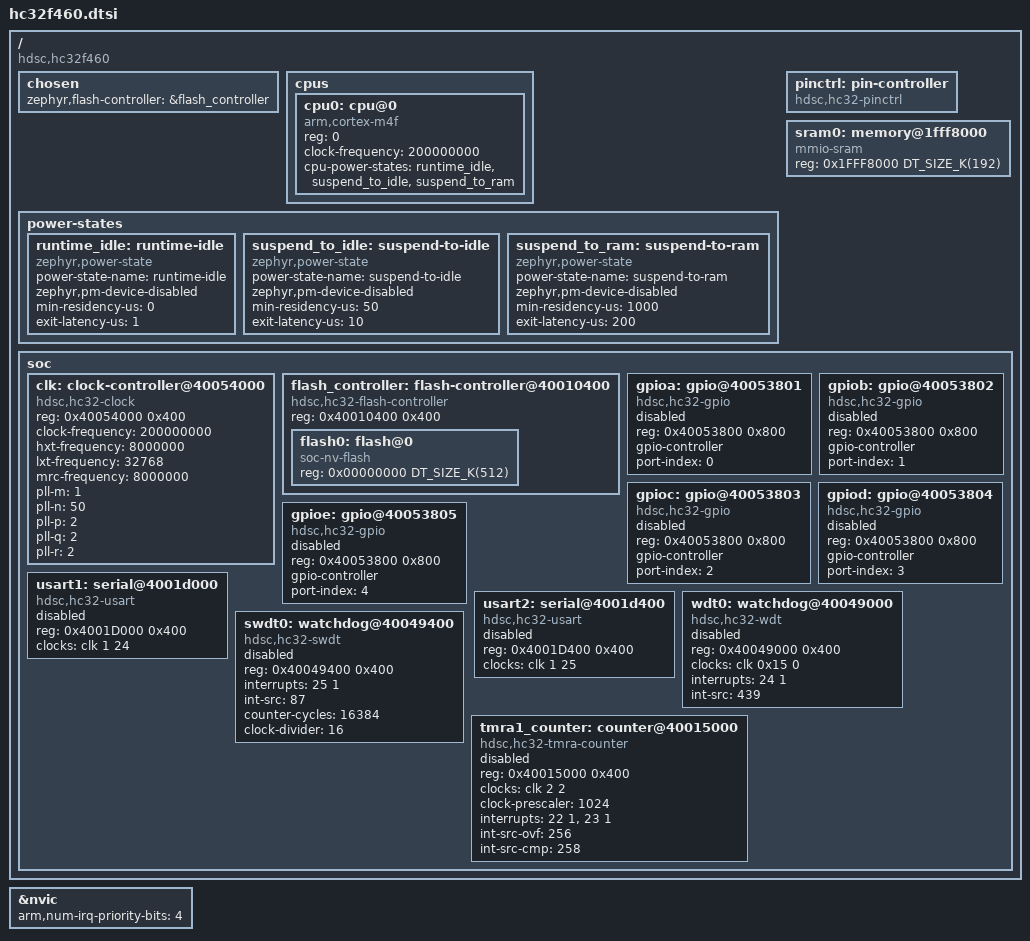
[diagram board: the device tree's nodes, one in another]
/*
 * SPDX-License-Identifier: Apache-2.0
 *
 * HC32F460 SoC devicetree include
 *
 * Memory map:
 *   Flash: 0x00000000, 512K
 *   SRAM:  0x1FFF8000, 192K (188K general + 4K ret_ram)
 */

#include <arm/armv7-m.dtsi>
#include <zephyr/dt-bindings/gpio/gpio.h>
#include <mem.h>

/ {
	compatible = "hdsc,hc32f460";

	chosen {
		zephyr,flash-controller = &flash_controller;
	};

	cpus {
		#address-cells = <1>;
		#size-cells = <0>;
		cpu0: cpu@0 {
			device_type = "cpu";
			compatible = "arm,cortex-m4f";
			reg = <0>;
			clock-frequency = <200000000>; /* HXT 8 MHz -> PLL 200 MHz */
			cpu-power-states = <&runtime_idle &suspend_to_idle &suspend_to_ram>;
		};
	};

	power-states {
		runtime_idle: runtime-idle {
			compatible = "zephyr,power-state";
			power-state-name = "runtime-idle";
			zephyr,pm-device-disabled;
			min-residency-us = <0>;
			exit-latency-us = <1>;
		};

		suspend_to_idle: suspend-to-idle {
			compatible = "zephyr,power-state";
			power-state-name = "suspend-to-idle";
			zephyr,pm-device-disabled;
			min-residency-us = <50>;
			exit-latency-us = <10>;
		};

		suspend_to_ram: suspend-to-ram {
			compatible = "zephyr,power-state";
			power-state-name = "suspend-to-ram";
			zephyr,pm-device-disabled;
			min-residency-us = <1000>;
			exit-latency-us = <200>;
		};
	};

	pinctrl: pin-controller {
		compatible = "hdsc,hc32-pinctrl";
		status = "okay";
	};

	sram0: memory@1fff8000 {
		compatible = "mmio-sram";
		reg = <0x1FFF8000 DT_SIZE_K(192)>;
	};

	soc {
		clk: clock-controller@40054000 {
			compatible = "hdsc,hc32-clock";
			reg = <0x40054000 0x400>;
			#clock-cells = <2>;
			clock-frequency = <200000000>;
			hxt-frequency = <8000000>;
			lxt-frequency = <32768>;
			mrc-frequency = <8000000>;
			pll-m = <1>;
			pll-n = <50>;
			pll-p = <2>;
			pll-q = <2>;
			pll-r = <2>;
			status = "okay";
		};

		flash_controller: flash-controller@40010400 {
			compatible = "hdsc,hc32-flash-controller";
			reg = <0x40010400 0x400>;
			#address-cells = <1>;
			#size-cells = <1>;

			flash0: flash@0 {
				compatible = "soc-nv-flash";
				reg = <0x00000000 DT_SIZE_K(512)>;
			};
		};

		gpioa: gpio@40053801 {
			compatible = "hdsc,hc32-gpio";
			reg = <0x40053800 0x800>;
			gpio-controller;
			#gpio-cells = <2>;
			port-index = <0>;  /* Port A */
			status = "disabled";
		};

		gpiob: gpio@40053802 {
			compatible = "hdsc,hc32-gpio";
			reg = <0x40053800 0x800>;
			gpio-controller;
			#gpio-cells = <2>;
			port-index = <1>;  /* Port B */
			status = "disabled";
		};

		gpioc: gpio@40053803 {
			compatible = "hdsc,hc32-gpio";
			reg = <0x40053800 0x800>;
			gpio-controller;
			#gpio-cells = <2>;
			port-index = <2>;  /* Port C */
			status = "disabled";
		};

		gpiod: gpio@40053804 {
			compatible = "hdsc,hc32-gpio";
			reg = <0x40053800 0x800>;
			gpio-controller;
			#gpio-cells = <2>;
			port-index = <3>;  /* Port D */
			status = "disabled";
		};

		gpioe: gpio@40053805 {
			compatible = "hdsc,hc32-gpio";
			reg = <0x40053800 0x800>;
			gpio-controller;
			#gpio-cells = <2>;
			port-index = <4>;  /* Port E */
			status = "disabled";
		};

		usart1: serial@4001d000 {
			compatible = "hdsc,hc32-usart";
			reg = <0x4001D000 0x400>;
			clocks = <&clk 1 24>;
			status = "disabled";
		};

		usart2: serial@4001d400 {
			compatible = "hdsc,hc32-usart";
			reg = <0x4001D400 0x400>;
			clocks = <&clk 1 25>;
			status = "disabled";
		};

		wdt0: watchdog@40049000 {
			compatible = "hdsc,hc32-wdt";
			reg = <0x40049000 0x400>;
			clocks = <&clk 0x15 0>; /* PCLK3 rate-only selector */
			interrupts = <24 1>;
			int-src = <439>;
			status = "disabled";
		};

		swdt0: watchdog@40049400 {
			compatible = "hdsc,hc32-swdt";
			reg = <0x40049400 0x400>;
			interrupts = <25 1>;
			int-src = <87>;
			counter-cycles = <16384>;
			clock-divider = <16>;
			status = "disabled";
		};

		tmra1_counter: counter@40015000 {
			compatible = "hdsc,hc32-tmra-counter";
			reg = <0x40015000 0x400>;
			clocks = <&clk 2 2>;
			clock-prescaler = <1024>;
			interrupts = <22 1>, <23 1>;
			interrupt-names = "ovf", "cmp";
			int-src-ovf = <256>;
			int-src-cmp = <258>;
			status = "disabled";
		};
	};
};

&nvic {
	arm,num-irq-priority-bits = <4>;
};
